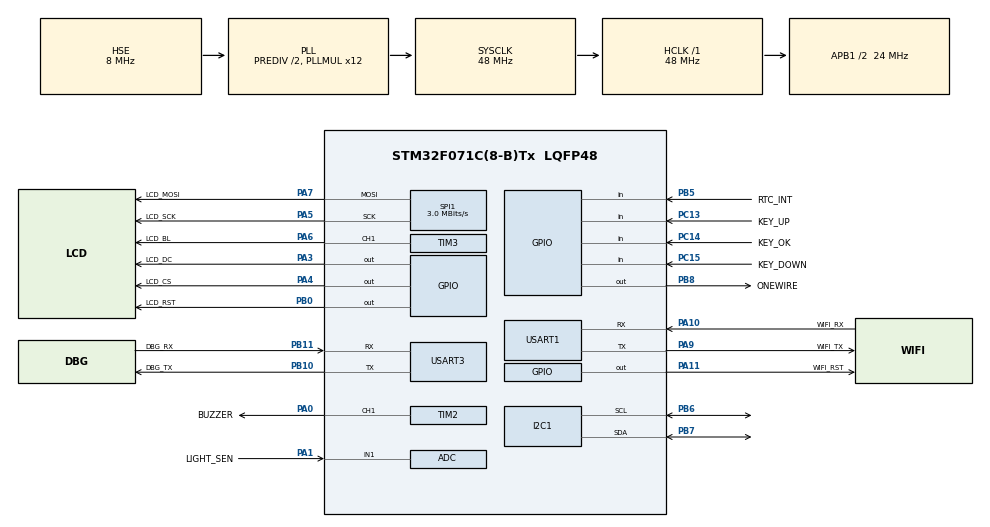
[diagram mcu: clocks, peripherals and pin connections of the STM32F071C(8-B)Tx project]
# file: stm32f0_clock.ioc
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ADC.ClockPrescaler=ADC_CLOCK_ASYNC_DIV1
ADC.ContinuousConvMode=DISABLE
ADC.DMAContinuousRequests=DISABLE
ADC.ExternalTrigConv=ADC_EXTERNALTRIGCONV_T15_TRGO
ADC.SamplingTime=ADC_SAMPLETIME_55CYCLES_5
I2C1.Timing=0x20303E5D
Mcu.Family=STM32F0
Mcu.Name=STM32F071C(8-B)Tx
Mcu.Package=LQFP48
NVIC.ADC1_COMP_IRQn=true\:1\:0\:true\:false\:true\:true\:true\:true
PA0.GPIO_Label=BUZZER
PA0.GPIO_ModeDefaultPP=GPIO_MODE_AF_PP
PA0.Signal=S_TIM2_CH1_ETR
PA1.GPIO_Label=LIGHT_SEN
PA1.Mode=IN1
PA1.Signal=ADC_IN1
PA10.GPIO_Label=WIFI_RX
PA10.GPIO_ModeDefaultPP=GPIO_MODE_AF_OD
PA10.GPIO_PuPd=GPIO_PULLUP
PA10.Mode=Asynchronous
PA10.Signal=USART1_RX
PA11.GPIO_Label=WIFI_RST
PA11.PinState=GPIO_PIN_SET
PA11.Signal=GPIO_Output
PA13.Mode=Serial_Wire
PA13.Signal=SYS_SWDIO
PA14.Mode=Serial_Wire
PA14.Signal=SYS_SWCLK
PA3.GPIO_Label=LCD_DC
PA3.GPIO_Speed=GPIO_SPEED_FREQ_HIGH
PA3.PinState=GPIO_PIN_SET
PA3.Signal=GPIO_Output
PA4.GPIO_Label=LCD_CS
PA4.GPIO_Speed=GPIO_SPEED_FREQ_HIGH
PA4.PinState=GPIO_PIN_SET
PA4.Signal=GPIO_Output
PA5.GPIO_Label=LCD_SCK
PA5.Mode=TX_Only_Simplex_Unidirect_Master
PA5.Signal=SPI1_SCK
PA6.GPIO_Label=LCD_BL
PA6.Signal=S_TIM3_CH1
PA7.GPIO_Label=LCD_MOSI
PA7.Mode=TX_Only_Simplex_Unidirect_Master
PA7.Signal=SPI1_MOSI
PA9.GPIO_Label=WIFI_TX
PA9.Mode=Asynchronous
PA9.Signal=USART1_TX
PB0.GPIO_Label=LCD_RST
PB0.Signal=GPIO_Output
PB10.GPIO_Label=DBG_TX
PB10.Mode=Asynchronous
PB10.Signal=USART3_TX
PB11.GPIO_Label=DBG_RX
PB11.GPIO_ModeDefaultPP=GPIO_MODE_AF_OD
PB11.GPIO_PuPd=GPIO_PULLUP
PB11.Mode=Asynchronous
PB11.Signal=USART3_RX
PB5.GPIO_Label=RTC_INT
PB5.GPIO_PuPd=GPIO_PULLUP
PB5.Signal=GPIO_Input
PB6.GPIO_Pu=GPIO_PULLUP
PB6.Mode=I2C
PB6.Signal=I2C1_SCL
PB7.GPIO_Pu=GPIO_PULLUP
PB7.Mode=I2C
PB7.Signal=I2C1_SDA
PB8.GPIO_FM8=__NULL
PB8.GPIO_Label=ONEWIRE
PB8.GPIO_ModeDefaultOutputPP=GPIO_MODE_OUTPUT_OD
PB8.GPIO_PuPd=GPIO_PULLUP
PB8.GPIO_Speed=GPIO_SPEED_FREQ_HIGH
PB8.PinState=GPIO_PIN_SET
PB8.Signal=GPIO_Output
PC13.GPIO_Label=KEY_UP
PC13.GPIO_PuPd=GPIO_PULLUP
PC13.Signal=GPIO_Input
PC14-OSC32_IN.GPIO_Label=KEY_OK
PC14-OSC32_IN.GPIO_PuPd=GPIO_PULLUP
PC14-OSC32_IN.Signal=GPIO_Input
PC15-OSC32_OUT.GPIO_Label=KEY_DOWN
PC15-OSC32_OUT.GPIO_PuPd=GPIO_PULLUP
PC15-OSC32_OUT.Signal=GPIO_Input
PF0-OSC_IN.Mode=HSE-External-Oscillator
PF0-OSC_IN.Signal=RCC_OSC_IN
PF1-OSC_OUT.Mode=HSE-External-Oscillator
PF1-OSC_OUT.Signal=RCC_OSC_OUT
ProjectManager.HeapSize=0x000
ProjectManager.StackSize=0x800
ProjectManager.TargetToolchain=MDK-ARM V5.32
RCC.AHBFreq_Value=48000000
RCC.APB1CLKDivider=RCC_HCLK_DIV2
RCC.APB1Freq_Value=24000000
RCC.APB1TimFreq_Value=48000000
RCC.EnbaleCSS=true
RCC.HCLKFreq_Value=48000000
RCC.I2c1ClockSelection=RCC_I2C1CLKSOURCE_SYSCLK
RCC.PLLDivider=RCC_PREDIV_DIV2
RCC.PLLMUL=RCC_PLL_MUL12
RCC.PLLSourceVirtual=RCC_PLLSOURCE_HSE
RCC.SYSCLKFreq_VALUE=48000000
RCC.SYSCLKSource=RCC_SYSCLKSOURCE_PLLCLK
SH.S_TIM2_CH1_ETR.0=TIM2_CH1,PWM Generation1 CH1
SH.S_TIM3_CH1.0=TIM3_CH1,PWM Generation1 CH1
SPI1.BaudRatePrescaler=SPI_BAUDRATEPRESCALER_8
SPI1.CalculateBaudRate=3.0 MBits/s
SPI1.DataSize=SPI_DATASIZE_8BIT
SPI1.Direction=SPI_DIRECTION_2LINES
SPI1.Mode=SPI_MODE_MASTER
SPI1.NSSPMode=SPI_NSS_PULSE_DISABLE
SPI1.VirtualType=VM_MASTER
TIM15.Period=50000-1
TIM15.Prescaler=480-1
TIM15.TIM_MasterOutputTrigger=TIM_TRGO_UPDATE
TIM2.AutoReloadPreload=TIM_AUTORELOAD_PRELOAD_ENABLE
TIM2.Channel-PWM\ Generation1\ CH1=TIM_CHANNEL_1
TIM2.Period=17777
TIM2.Prescaler=0
TIM2.Pulse-PWM\ Generation1\ CH1=3555
TIM3.AutoReloadPreload=TIM_AUTORELOAD_PRELOAD_ENABLE
TIM3.Channel-PWM\ Generation1\ CH1=TIM_CHANNEL_1
TIM3.Period=4800-1
TIM3.Prescaler=0
TIM3.Pulse-PWM\ Generation1\ CH1=800
TIM6.AutoReloadPreload=TIM_AUTORELOAD_PRELOAD_DISABLE
TIM6.Prescaler=48-1
USART1.VirtualMode-Asynchronous=VM_ASYNC
USART3.VirtualMode-Asynchronous=VM_ASYNC
VP_TIM15_VS_ClockSourceINT.Mode=Internal
VP_TIM6_VS_ClockSourceINT.Mode=Enable_Timer
board=custom

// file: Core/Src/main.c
/* USER CODE BEGIN Header */
/**
  ******************************************************************************
  * @file           : main.c
  * @brief          : Main program body
  ******************************************************************************
  * @attention
  *
  * Copyright (c) 2023 STMicroelectronics.
  * All rights reserved.
  *
  * This software is licensed under terms that can be found in the LICENSE file
  * in the root directory of this software component.
  * If no LICENSE file comes with this software, it is provided AS-IS.
  *
  ******************************************************************************
  */
/* USER CODE END Header */
#include "main.h"

/* USER CODE BEGIN Includes */
#include "app_main.h"
/* USER CODE END Includes */

ADC_HandleTypeDef hadc;

I2C_HandleTypeDef hi2c1;

SPI_HandleTypeDef hspi1;

TIM_HandleTypeDef htim2;
TIM_HandleTypeDef htim3;
TIM_HandleTypeDef htim6;
TIM_HandleTypeDef htim15;

UART_HandleTypeDef huart1;
UART_HandleTypeDef huart3;

void SystemClock_Config(void);
static void MX_GPIO_Init(void);
static void MX_ADC_Init(void);
static void MX_I2C1_Init(void);
static void MX_SPI1_Init(void);
static void MX_TIM2_Init(void);
static void MX_TIM3_Init(void);
static void MX_USART1_UART_Init(void);
static void MX_USART3_UART_Init(void);
static void MX_TIM6_Init(void);
static void MX_TIM15_Init(void);

int main(void)
{

  /* MCU Configuration--------------------------------------------------------*/

  /* Reset of all peripherals, Initializes the Flash interface and the Systick. */
  HAL_Init();

  /* Configure the system clock */
  SystemClock_Config();

  /* Initialize all configured peripherals */
  MX_GPIO_Init();
  MX_ADC_Init();
  MX_I2C1_Init();
  MX_SPI1_Init();
  MX_TIM2_Init();
  MX_TIM3_Init();
  MX_USART1_UART_Init();
  MX_USART3_UART_Init();
  MX_TIM6_Init();
  MX_TIM15_Init();
  /* USER CODE BEGIN 2 */
  app_init();
  /* USER CODE END 2 */

  /* Infinite loop */
  /* USER CODE BEGIN WHILE */
  app_main();
    /* USER CODE END WHILE */

}

void SystemClock_Config(void)
{
  RCC_OscInitTypeDef RCC_OscInitStruct = {0};
  RCC_ClkInitTypeDef RCC_ClkInitStruct = {0};
  RCC_PeriphCLKInitTypeDef PeriphClkInit = {0};

  /** Initializes the RCC Oscillators according to the specified parameters
  * in the RCC_OscInitTypeDef structure.
  */
  RCC_OscInitStruct.OscillatorType = RCC_OSCILLATORTYPE_HSI14|RCC_OSCILLATORTYPE_HSE;
  RCC_OscInitStruct.HSEState = RCC_HSE_ON;
  RCC_OscInitStruct.HSI14State = RCC_HSI14_ON;
  RCC_OscInitStruct.HSI14CalibrationValue = 16;
  RCC_OscInitStruct.PLL.PLLState = RCC_PLL_ON;
  RCC_OscInitStruct.PLL.PLLSource = RCC_PLLSOURCE_HSE;
  RCC_OscInitStruct.PLL.PLLMUL = RCC_PLL_MUL12;
  RCC_OscInitStruct.PLL.PREDIV = RCC_PREDIV_DIV2;
  if (HAL_RCC_OscConfig(&RCC_OscInitStruct) != HAL_OK)
  {
    Error_Handler();
  }

  /** Initializes the CPU, AHB and APB buses clocks
  */
  RCC_ClkInitStruct.ClockType = RCC_CLOCKTYPE_HCLK|RCC_CLOCKTYPE_SYSCLK
                              |RCC_CLOCKTYPE_PCLK1;
  RCC_ClkInitStruct.SYSCLKSource = RCC_SYSCLKSOURCE_PLLCLK;
  RCC_ClkInitStruct.AHBCLKDivider = RCC_SYSCLK_DIV1;
  RCC_ClkInitStruct.APB1CLKDivider = RCC_HCLK_DIV2;

  if (HAL_RCC_ClockConfig(&RCC_ClkInitStruct, FLASH_LATENCY_1) != HAL_OK)
  {
    Error_Handler();
  }
  PeriphClkInit.PeriphClockSelection = RCC_PERIPHCLK_USART1|RCC_PERIPHCLK_I2C1;
  PeriphClkInit.Usart1ClockSelection = RCC_USART1CLKSOURCE_PCLK1;
  PeriphClkInit.I2c1ClockSelection = RCC_I2C1CLKSOURCE_SYSCLK;
  if (HAL_RCCEx_PeriphCLKConfig(&PeriphClkInit) != HAL_OK)
  {
    Error_Handler();
  }

  /** Enables the Clock Security System
  */
  HAL_RCC_EnableCSS();
}

static void MX_ADC_Init(void)
{

  ADC_ChannelConfTypeDef sConfig = {0};

  /** Configure the global features of the ADC (Clock, Resolution, Data Alignment and number of conversion)
  */
  hadc.Instance = ADC1;
  hadc.Init.ClockPrescaler = ADC_CLOCK_ASYNC_DIV1;
  hadc.Init.Resolution = ADC_RESOLUTION_12B;
  hadc.Init.DataAlign = ADC_DATAALIGN_RIGHT;
  hadc.Init.ScanConvMode = ADC_SCAN_DIRECTION_FORWARD;
  hadc.Init.EOCSelection = ADC_EOC_SINGLE_CONV;
  hadc.Init.LowPowerAutoWait = DISABLE;
  hadc.Init.LowPowerAutoPowerOff = DISABLE;
  hadc.Init.ContinuousConvMode = DISABLE;
  hadc.Init.DiscontinuousConvMode = DISABLE;
  hadc.Init.ExternalTrigConv = ADC_EXTERNALTRIGCONV_T15_TRGO;
  hadc.Init.ExternalTrigConvEdge = ADC_EXTERNALTRIGCONVEDGE_RISING;
  hadc.Init.DMAContinuousRequests = DISABLE;
  hadc.Init.Overrun = ADC_OVR_DATA_PRESERVED;
  if (HAL_ADC_Init(&hadc) != HAL_OK)
  {
    Error_Handler();
  }

  /** Configure for the selected ADC regular channel to be converted.
  */
  sConfig.Channel = ADC_CHANNEL_1;
  sConfig.Rank = ADC_RANK_CHANNEL_NUMBER;
  sConfig.SamplingTime = ADC_SAMPLETIME_55CYCLES_5;
  if (HAL_ADC_ConfigChannel(&hadc, &sConfig) != HAL_OK)
  {
    Error_Handler();
  }

}

static void MX_I2C1_Init(void)
{

  hi2c1.Instance = I2C1;
  hi2c1.Init.Timing = 0x20303E5D;
  hi2c1.Init.OwnAddress1 = 0;
  hi2c1.Init.AddressingMode = I2C_ADDRESSINGMODE_7BIT;
  hi2c1.Init.DualAddressMode = I2C_DUALADDRESS_DISABLE;
  hi2c1.Init.OwnAddress2 = 0;
  hi2c1.Init.OwnAddress2Masks = I2C_OA2_NOMASK;
  hi2c1.Init.GeneralCallMode = I2C_GENERALCALL_DISABLE;
  hi2c1.Init.NoStretchMode = I2C_NOSTRETCH_DISABLE;
  if (HAL_I2C_Init(&hi2c1) != HAL_OK)
  {
    Error_Handler();
  }

  /** Configure Analogue filter
  */
  if (HAL_I2CEx_ConfigAnalogFilter(&hi2c1, I2C_ANALOGFILTER_ENABLE) != HAL_OK)
  {
    Error_Handler();
  }

  /** Configure Digital filter
  */
  if (HAL_I2CEx_ConfigDigitalFilter(&hi2c1, 0) != HAL_OK)
  {
    Error_Handler();
  }

}

static void MX_SPI1_Init(void)
{

  /* SPI1 parameter configuration*/
  hspi1.Instance = SPI1;
  hspi1.Init.Mode = SPI_MODE_MASTER;
  hspi1.Init.Direction = SPI_DIRECTION_2LINES;
  hspi1.Init.DataSize = SPI_DATASIZE_8BIT;
  hspi1.Init.CLKPolarity = SPI_POLARITY_LOW;
  hspi1.Init.CLKPhase = SPI_PHASE_1EDGE;
  hspi1.Init.NSS = SPI_NSS_SOFT;
  hspi1.Init.BaudRatePrescaler = SPI_BAUDRATEPRESCALER_8;
  hspi1.Init.FirstBit = SPI_FIRSTBIT_MSB;
  hspi1.Init.TIMode = SPI_TIMODE_DISABLE;
  hspi1.Init.CRCCalculation = SPI_CRCCALCULATION_DISABLE;
  hspi1.Init.CRCPolynomial = 7;
  hspi1.Init.CRCLength = SPI_CRC_LENGTH_DATASIZE;
  hspi1.Init.NSSPMode = SPI_NSS_PULSE_DISABLE;
  if (HAL_SPI_Init(&hspi1) != HAL_OK)
  {
    Error_Handler();
  }

}

static void MX_TIM2_Init(void)
{

  TIM_MasterConfigTypeDef sMasterConfig = {0};
  TIM_OC_InitTypeDef sConfigOC = {0};

  htim2.Instance = TIM2;
  htim2.Init.Prescaler = 0;
  htim2.Init.CounterMode = TIM_COUNTERMODE_UP;
  htim2.Init.Period = 17777;
  htim2.Init.ClockDivision = TIM_CLOCKDIVISION_DIV1;
  htim2.Init.AutoReloadPreload = TIM_AUTORELOAD_PRELOAD_ENABLE;
  if (HAL_TIM_PWM_Init(&htim2) != HAL_OK)
  {
    Error_Handler();
  }
  sMasterConfig.MasterOutputTrigger = TIM_TRGO_RESET;
  sMasterConfig.MasterSlaveMode = TIM_MASTERSLAVEMODE_DISABLE;
  if (HAL_TIMEx_MasterConfigSynchronization(&htim2, &sMasterConfig) != HAL_OK)
  {
    Error_Handler();
  }
  sConfigOC.OCMode = TIM_OCMODE_PWM1;
  sConfigOC.Pulse = 3555;
  sConfigOC.OCPolarity = TIM_OCPOLARITY_HIGH;
  sConfigOC.OCFastMode = TIM_OCFAST_DISABLE;
  if (HAL_TIM_PWM_ConfigChannel(&htim2, &sConfigOC, TIM_CHANNEL_1) != HAL_OK)
  {
    Error_Handler();
  }
  HAL_TIM_MspPostInit(&htim2);

}

static void MX_TIM3_Init(void)
{

  TIM_MasterConfigTypeDef sMasterConfig = {0};
  TIM_OC_InitTypeDef sConfigOC = {0};

  htim3.Instance = TIM3;
  htim3.Init.Prescaler = 0;
  htim3.Init.CounterMode = TIM_COUNTERMODE_UP;
  htim3.Init.Period = 4800-1;
  htim3.Init.ClockDivision = TIM_CLOCKDIVISION_DIV1;
  htim3.Init.AutoReloadPreload = TIM_AUTORELOAD_PRELOAD_ENABLE;
  if (HAL_TIM_PWM_Init(&htim3) != HAL_OK)
  {
    Error_Handler();
  }
  sMasterConfig.MasterOutputTrigger = TIM_TRGO_RESET;
  sMasterConfig.MasterSlaveMode = TIM_MASTERSLAVEMODE_DISABLE;
  if (HAL_TIMEx_MasterConfigSynchronization(&htim3, &sMasterConfig) != HAL_OK)
  {
    Error_Handler();
  }
  sConfigOC.OCMode = TIM_OCMODE_PWM1;
  sConfigOC.Pulse = 800;
  sConfigOC.OCPolarity = TIM_OCPOLARITY_HIGH;
  sConfigOC.OCFastMode = TIM_OCFAST_DISABLE;
  if (HAL_TIM_PWM_ConfigChannel(&htim3, &sConfigOC, TIM_CHANNEL_1) != HAL_OK)
  {
    Error_Handler();
  }
  HAL_TIM_MspPostInit(&htim3);

}

static void MX_TIM6_Init(void)
{

  TIM_MasterConfigTypeDef sMasterConfig = {0};

  htim6.Instance = TIM6;
  htim6.Init.Prescaler = 48-1;
  htim6.Init.CounterMode = TIM_COUNTERMODE_UP;
  htim6.Init.Period = 65535;
  htim6.Init.AutoReloadPreload = TIM_AUTORELOAD_PRELOAD_DISABLE;
  if (HAL_TIM_Base_Init(&htim6) != HAL_OK)
  {
    Error_Handler();
  }
  sMasterConfig.MasterOutputTrigger = TIM_TRGO_RESET;
  sMasterConfig.MasterSlaveMode = TIM_MASTERSLAVEMODE_DISABLE;
  if (HAL_TIMEx_MasterConfigSynchronization(&htim6, &sMasterConfig) != HAL_OK)
  {
    Error_Handler();
  }

}

static void MX_TIM15_Init(void)
{

  TIM_ClockConfigTypeDef sClockSourceConfig = {0};
  TIM_MasterConfigTypeDef sMasterConfig = {0};

  htim15.Instance = TIM15;
  htim15.Init.Prescaler = 480-1;
  htim15.Init.CounterMode = TIM_COUNTERMODE_UP;
  htim15.Init.Period = 50000-1;
  htim15.Init.ClockDivision = TIM_CLOCKDIVISION_DIV1;
  htim15.Init.RepetitionCounter = 0;
  htim15.Init.AutoReloadPreload = TIM_AUTORELOAD_PRELOAD_DISABLE;
  if (HAL_TIM_Base_Init(&htim15) != HAL_OK)
  {
    Error_Handler();
  }
  sClockSourceConfig.ClockSource = TIM_CLOCKSOURCE_INTERNAL;
  if (HAL_TIM_ConfigClockSource(&htim15, &sClockSourceConfig) != HAL_OK)
  {
    Error_Handler();
  }
  sMasterConfig.MasterOutputTrigger = TIM_TRGO_UPDATE;
  sMasterConfig.MasterSlaveMode = TIM_MASTERSLAVEMODE_DISABLE;
  if (HAL_TIMEx_MasterConfigSynchronization(&htim15, &sMasterConfig) != HAL_OK)
  {
    Error_Handler();
  }

}

static void MX_USART1_UART_Init(void)
{

  huart1.Instance = USART1;
  huart1.Init.BaudRate = 38400;
  huart1.Init.WordLength = UART_WORDLENGTH_8B;
  huart1.Init.StopBits = UART_STOPBITS_1;
  huart1.Init.Parity = UART_PARITY_NONE;
  huart1.Init.Mode = UART_MODE_TX_RX;
  huart1.Init.HwFlowCtl = UART_HWCONTROL_NONE;
  huart1.Init.OverSampling = UART_OVERSAMPLING_16;
  huart1.Init.OneBitSampling = UART_ONE_BIT_SAMPLE_DISABLE;
  huart1.AdvancedInit.AdvFeatureInit = UART_ADVFEATURE_NO_INIT;
  if (HAL_UART_Init(&huart1) != HAL_OK)
  {
    Error_Handler();
  }

}

static void MX_USART3_UART_Init(void)
{

  huart3.Instance = USART3;
  huart3.Init.BaudRate = 38400;
  huart3.Init.WordLength = UART_WORDLENGTH_8B;
  huart3.Init.StopBits = UART_STOPBITS_1;
  huart3.Init.Parity = UART_PARITY_NONE;
  huart3.Init.Mode = UART_MODE_TX_RX;
  huart3.Init.HwFlowCtl = UART_HWCONTROL_NONE;
  huart3.Init.OverSampling = UART_OVERSAMPLING_16;
  huart3.Init.OneBitSampling = UART_ONE_BIT_SAMPLE_DISABLE;
  huart3.AdvancedInit.AdvFeatureInit = UART_ADVFEATURE_NO_INIT;
  if (HAL_UART_Init(&huart3) != HAL_OK)
  {
    Error_Handler();
  }

}

static void MX_GPIO_Init(void)
{
  GPIO_InitTypeDef GPIO_InitStruct = {0};

  /* GPIO Ports Clock Enable */
  __HAL_RCC_GPIOC_CLK_ENABLE();
  __HAL_RCC_GPIOF_CLK_ENABLE();
  __HAL_RCC_GPIOA_CLK_ENABLE();
  __HAL_RCC_GPIOB_CLK_ENABLE();

  /*Configure GPIO pin Output Level */
  HAL_GPIO_WritePin(GPIOA, LCD_DC_Pin|LCD_CS_Pin|WIFI_RST_Pin, GPIO_PIN_SET);

  /*Configure GPIO pin Output Level */
  HAL_GPIO_WritePin(LCD_RST_GPIO_Port, LCD_RST_Pin, GPIO_PIN_RESET);

  /*Configure GPIO pin Output Level */
  HAL_GPIO_WritePin(ONEWIRE_GPIO_Port, ONEWIRE_Pin, GPIO_PIN_SET);

  /*Configure GPIO pins : KEY_UP_Pin KEY_OK_Pin KEY_DOWN_Pin */
  GPIO_InitStruct.Pin = KEY_UP_Pin|KEY_OK_Pin|KEY_DOWN_Pin;
  GPIO_InitStruct.Mode = GPIO_MODE_INPUT;
  GPIO_InitStruct.Pull = GPIO_PULLUP;
  HAL_GPIO_Init(GPIOC, &GPIO_InitStruct);

  /*Configure GPIO pins : LCD_DC_Pin LCD_CS_Pin */
  GPIO_InitStruct.Pin = LCD_DC_Pin|LCD_CS_Pin;
  GPIO_InitStruct.Mode = GPIO_MODE_OUTPUT_PP;
  GPIO_InitStruct.Pull = GPIO_NOPULL;
  GPIO_InitStruct.Speed = GPIO_SPEED_FREQ_HIGH;
  HAL_GPIO_Init(GPIOA, &GPIO_InitStruct);

  /*Configure GPIO pin : LCD_RST_Pin */
  GPIO_InitStruct.Pin = LCD_RST_Pin;
  GPIO_InitStruct.Mode = GPIO_MODE_OUTPUT_PP;
  GPIO_InitStruct.Pull = GPIO_NOPULL;
  GPIO_InitStruct.Speed = GPIO_SPEED_FREQ_LOW;
  HAL_GPIO_Init(LCD_RST_GPIO_Port, &GPIO_InitStruct);

  /*Configure GPIO pin : WIFI_RST_Pin */
  GPIO_InitStruct.Pin = WIFI_RST_Pin;
  GPIO_InitStruct.Mode = GPIO_MODE_OUTPUT_PP;
  GPIO_InitStruct.Pull = GPIO_NOPULL;
  GPIO_InitStruct.Speed = GPIO_SPEED_FREQ_LOW;
  HAL_GPIO_Init(WIFI_RST_GPIO_Port, &GPIO_InitStruct);

  /*Configure GPIO pin : RTC_INT_Pin */
  GPIO_InitStruct.Pin = RTC_INT_Pin;
  GPIO_InitStruct.Mode = GPIO_MODE_INPUT;
  GPIO_InitStruct.Pull = GPIO_PULLUP;
  HAL_GPIO_Init(RTC_INT_GPIO_Port, &GPIO_InitStruct);

  /*Configure GPIO pin : ONEWIRE_Pin */
  GPIO_InitStruct.Pin = ONEWIRE_Pin;
  GPIO_InitStruct.Mode = GPIO_MODE_OUTPUT_OD;
  GPIO_InitStruct.Pull = GPIO_PULLUP;
  GPIO_InitStruct.Speed = GPIO_SPEED_FREQ_HIGH;
  HAL_GPIO_Init(ONEWIRE_GPIO_Port, &GPIO_InitStruct);

}

void Error_Handler(void)
{
  __disable_irq();
  while (1)
  {
  }
}
